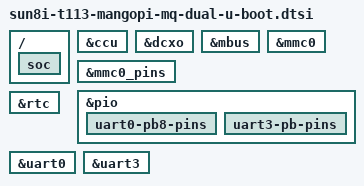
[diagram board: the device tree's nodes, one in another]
// SPDX-License-Identifier: (GPL-2.0 OR MIT)

#include "sunxi-u-boot.dtsi"

/ {
	soc {
		u-boot,dm-spl;
	};
};

&ccu {
	u-boot,dm-spl;
};

&dcxo {
	u-boot,dm-spl;
};

&mbus {
	u-boot,dm-spl;
};

&mmc0 {
	u-boot,dm-spl;
};

&mmc0_pins {
	u-boot,dm-spl;
};

&pio {
	u-boot,dm-spl;

	uart0-pb8-pins {
		u-boot,dm-spl;
	};

	uart3-pb-pins {
		u-boot,dm-spl;
	};
};

&rtc {
	u-boot,dm-spl;
};

&uart0 {
	u-boot,dm-spl;
};

&uart3 {
	u-boot,dm-spl;
};
